AUTOSAR XML (schema 4-0-3)
package /MotorComposition
  sender receiver interface SR_PWM
    data pwm_data: type=sint8
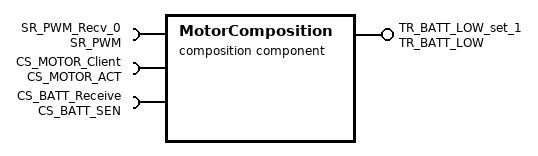
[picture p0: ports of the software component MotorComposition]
  composition sw component type MotorComposition
    require port SR_PWM_Recv_0: required-interface=SR_PWM
    provide port TR_BATT_LOW_set_1: provided-interface=TR_BATT_LOW
    require port CS_MOTOR_Client: required-interface=CS_MOTOR_ACT
    require port CS_BATT_Receive: required-interface=CS_BATT_SEN
    component CPT_APP_MOTOR_COMP: type=APP_MOTOR_COMP
    component CPT_SEN_BATT_COMP: type=SEN_BATT_COMP
    component CPT_ACT_MOTOR_COMP: type=ACT_MOTOR_COMP
    connect CPT_APP_MOTOR_COMP.SR_MOTOR_SPEED_Send -> CPT_ACT_MOTOR_COMP.SR_MOTOR_SPEED_Recv
    connect CPT_SEN_BATT_COMP.SR_BATT_Send -> CPT_APP_MOTOR_COMP.SR_BATT_Recv
    delegate CPT_APP_MOTOR_COMP.SR_PWM_Recv <-> outer port SR_PWM_Recv_0
    delegate CPT_APP_MOTOR_COMP.TR_BATT_LOW_set <-> outer port TR_BATT_LOW_set_1
    delegate CPT_ACT_MOTOR_COMP.CS_MOTOR_Client <-> outer port MotorComposition/CS_MOTOR_Client
    delegate CPT_SEN_BATT_COMP.CS_BATT_Receive <-> outer port MotorComposition/CS_BATT_Receive
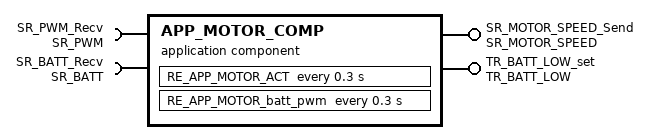
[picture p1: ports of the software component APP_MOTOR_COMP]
  application sw component type APP_MOTOR_COMP
    require port SR_PWM_Recv: required-interface=SR_PWM
    provide port SR_MOTOR_SPEED_Send: provided-interface=SR_MOTOR_SPEED
    require port SR_BATT_Recv: required-interface=SR_BATT
    provide port TR_BATT_LOW_set: provided-interface=TR_BATT_LOW
    behavior IB_APP_MOTOR
      timing event TE_300ms: start-on-event=RE_APP_MOTOR_ACT, period=0.3
      timing event TimingEvent_0: start-on-event=RE_APP_MOTOR_batt_pwm, period=0.3
      runnable RE_APP_MOTOR_batt_pwm: external-triggering-points=[TR_BATT_LOW_set.normal, TR_BATT_LOW_set.low], symbol=RE_APP_MOTOR_batt_pwm_func
        data-receive-point-by-values:
          access DRPV_batt_data_0: accessed-variable=SR_BATT_Recv.batt_data
          access DRPV_pwm_data_0: accessed-variable=SR_PWM_Recv.pwm_data
      runnable RE_APP_MOTOR_ACT: symbol=RE_APP_MOTOR_ACT_func
        data-send-points:
          access DSP_motor_speed_data_0: accessed-variable=SR_MOTOR_SPEED_Send.motor_speed_data
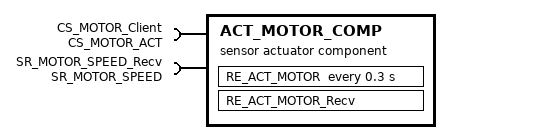
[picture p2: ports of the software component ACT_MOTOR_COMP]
  sensor actuator sw component type ACT_MOTOR_COMP
    require port CS_MOTOR_Client: required-interface=CS_MOTOR_ACT
    require port SR_MOTOR_SPEED_Recv: required-interface=SR_MOTOR_SPEED
    behavior IB_ACT_MOTOR_COMP
      timing event TE_ServerCall_100ms: start-on-event=RE_ACT_MOTOR, period=0.3
      runnable RE_ACT_MOTOR: symbol=RE_ACT_MOTOR_func
        sync call SynchronousServerCallPoint_0: operation=CS_MOTOR_Client.motor_act_op
      runnable RE_ACT_MOTOR_Recv: symbol=RE_ACT_MOTOR_Recv_func
        data-receive-point-by-values:
          access DRPV_motor_speed_data_0: accessed-variable=SR_MOTOR_SPEED_Recv.motor_speed_data
  sender receiver interface SR_MOTOR_SPEED
    data motor_speed_data: type=sint16
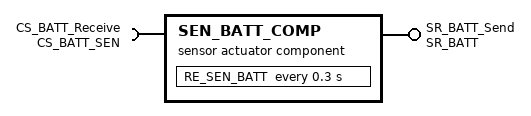
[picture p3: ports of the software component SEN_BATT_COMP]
  sensor actuator sw component type SEN_BATT_COMP
    provide port SR_BATT_Send: provided-interface=SR_BATT
    require port CS_BATT_Receive: required-interface=CS_BATT_SEN
    behavior IB_SEN_BATT_COMP
      timing event TE_300ms: start-on-event=RE_SEN_BATT, period=0.3
      runnable RE_SEN_BATT: symbol=RE_SEN_BATT_func
        data-send-points:
          access DSP_batt_data_0: accessed-variable=SR_BATT_Send.batt_data
        sync call SynchronousServerCallPoint_0: operation=CS_BATT_Receive.batt_sen_op
  client server interface CS_MOTOR_ACT
    operation motor_act_op
      arg motor_act_data: type=sint16, direction=IN, server-argument-impl-policy=USE-ARGUMENT-TYPE
  client server interface CS_BATT_SEN
    operation batt_sen_op
      arg batt_sen_data: type=uint8, direction=OUT, server-argument-impl-policy=USE-ARGUMENT-TYPE
  sender receiver interface SR_BATT
    data batt_data: type=uint8
  trigger interface TR_BATT_LOW
    trigger normal
    trigger low
